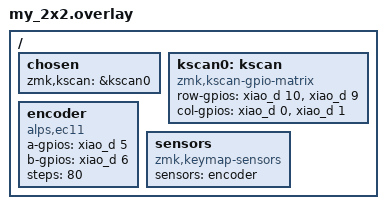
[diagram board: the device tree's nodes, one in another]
#include <dt-bindings/gpio/gpio.h>

/ {

    chosen {
        zmk,kscan = &kscan0;
    };

    kscan0: kscan {
        compatible = "zmk,kscan-gpio-matrix";

        row-gpios
            = <&xiao_d 10 GPIO_ACTIVE_HIGH>
            , <&xiao_d 9 GPIO_ACTIVE_HIGH>
            ;

        col-gpios
            = <&xiao_d 0 GPIO_ACTIVE_HIGH>
            , <&xiao_d 1 GPIO_ACTIVE_HIGH>
            ;
    };

    encoder: encoder {
        compatible = "alps,ec11";
        a-gpios = <&xiao_d 5 (GPIO_ACTIVE_HIGH | GPIO_PULL_UP)>;
        b-gpios = <&xiao_d 6 (GPIO_ACTIVE_HIGH | GPIO_PULL_UP)>;
        steps = <80>;
        status = "okay";
    };

    sensors {
        compatible = "zmk,keymap-sensors";
        sensors = <&encoder>;
    };
};
